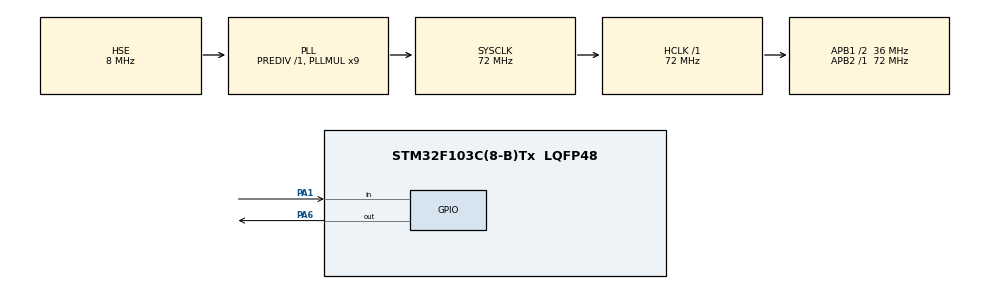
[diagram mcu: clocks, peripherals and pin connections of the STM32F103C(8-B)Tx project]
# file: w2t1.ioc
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Mcu.Family=STM32F1
Mcu.Name=STM32F103C(8-B)Tx
Mcu.Package=LQFP48
NVIC.PriorityGroup=NVIC_PRIORITYGROUP_4
NVIC.TIM2_IRQn=true\:0\:0\:false\:false\:true\:true\:true\:true
PA1.GPIO_PuPd=GPIO_PULLUP
PA1.Signal=GPIO_Input
PA13.Mode=Serial_Wire
PA13.Signal=SYS_JTMS-SWDIO
PA14.Mode=Serial_Wire
PA14.Signal=SYS_JTCK-SWCLK
PA6.PinState=GPIO_PIN_SET
PA6.Signal=GPIO_Output
PD0-OSC_IN.Mode=HSE-External-Oscillator
PD0-OSC_IN.Signal=RCC_OSC_IN
PD1-OSC_OUT.Mode=HSE-External-Oscillator
PD1-OSC_OUT.Signal=RCC_OSC_OUT
ProjectManager.HeapSize=0x200
ProjectManager.StackSize=0x400
ProjectManager.TargetToolchain=MDK-ARM V5.32
RCC.AHBFreq_Value=72000000
RCC.APB1CLKDivider=RCC_HCLK_DIV2
RCC.APB1Freq_Value=36000000
RCC.APB1TimFreq_Value=72000000
RCC.APB2Freq_Value=72000000
RCC.APB2TimFreq_Value=72000000
RCC.HCLKFreq_Value=72000000
RCC.PLLMUL=RCC_PLL_MUL9
RCC.PLLSourceVirtual=RCC_PLLSOURCE_HSE
RCC.SYSCLKFreq_VALUE=72000000
RCC.SYSCLKSource=RCC_SYSCLKSOURCE_PLLCLK
RCC.USBFreq_Value=72000000
TIM2.Period=9999
TIM2.Prescaler=71
VP_TIM2_VS_ClockSourceINT.Mode=Internal
board=custom

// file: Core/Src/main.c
/* USER CODE BEGIN Header */
/**
  ******************************************************************************
  * @file           : main.c
  * @brief          : Main program body
  ******************************************************************************
  * @attention
  *
  * Copyright (c) 2026 STMicroelectronics.
  * All rights reserved.
  *
  * This software is licensed under terms that can be found in the LICENSE file
  * in the root directory of this software component.
  * If no LICENSE file comes with this software, it is provided AS-IS.
  *
  ******************************************************************************
  */
/* USER CODE END Header */
#include "main.h"
#include "stm32f103xb.h"
#include "stm32f1xx_hal_gpio.h"
#include "stm32f1xx_hal_tim.h"
#include <stdint.h>

TIM_HandleTypeDef htim2;

/* USER CODE BEGIN PV */
uint8_t key_state = 0;
uint16_t press_cnt = 0;
uint8_t is_5hz = 0;
uint8_t led_mode = 0; // 0 是灭 1 是亮
uint8_t nowledpin = 0;
uint16_t blink_cnt = 0;

/* USER CODE END PV */

void SystemClock_Config(void);
static void MX_GPIO_Init(void);
static void MX_TIM2_Init(void);

int main(void)
{

  /* MCU Configuration--------------------------------------------------------*/

  /* Reset of all peripherals, Initializes the Flash interface and the Systick. */
  HAL_Init();

  /* Configure the system clock */
  SystemClock_Config();

  /* Initialize all configured peripherals */
  MX_GPIO_Init();
  MX_TIM2_Init();
  /* USER CODE BEGIN 2 */
HAL_TIM_Base_Start_IT(&htim2);
  /* USER CODE END 2 */

  /* Infinite loop */
  while (1)
  {

  }
}

void SystemClock_Config(void)
{
  RCC_OscInitTypeDef RCC_OscInitStruct = {0};
  RCC_ClkInitTypeDef RCC_ClkInitStruct = {0};

  /** Initializes the RCC Oscillators according to the specified parameters
  * in the RCC_OscInitTypeDef structure.
  */
  RCC_OscInitStruct.OscillatorType = RCC_OSCILLATORTYPE_HSE;
  RCC_OscInitStruct.HSEState = RCC_HSE_ON;
  RCC_OscInitStruct.HSEPredivValue = RCC_HSE_PREDIV_DIV1;
  RCC_OscInitStruct.HSIState = RCC_HSI_ON;
  RCC_OscInitStruct.PLL.PLLState = RCC_PLL_ON;
  RCC_OscInitStruct.PLL.PLLSource = RCC_PLLSOURCE_HSE;
  RCC_OscInitStruct.PLL.PLLMUL = RCC_PLL_MUL9;
  if (HAL_RCC_OscConfig(&RCC_OscInitStruct) != HAL_OK)
  {
    Error_Handler();
  }

  /** Initializes the CPU, AHB and APB buses clocks
  */
  RCC_ClkInitStruct.ClockType = RCC_CLOCKTYPE_HCLK|RCC_CLOCKTYPE_SYSCLK
                              |RCC_CLOCKTYPE_PCLK1|RCC_CLOCKTYPE_PCLK2;
  RCC_ClkInitStruct.SYSCLKSource = RCC_SYSCLKSOURCE_PLLCLK;
  RCC_ClkInitStruct.AHBCLKDivider = RCC_SYSCLK_DIV1;
  RCC_ClkInitStruct.APB1CLKDivider = RCC_HCLK_DIV2;
  RCC_ClkInitStruct.APB2CLKDivider = RCC_HCLK_DIV1;

  if (HAL_RCC_ClockConfig(&RCC_ClkInitStruct, FLASH_LATENCY_2) != HAL_OK)
  {
    Error_Handler();
  }
}

static void MX_TIM2_Init(void)
{

  TIM_ClockConfigTypeDef sClockSourceConfig = {0};
  TIM_MasterConfigTypeDef sMasterConfig = {0};

  htim2.Instance = TIM2;
  htim2.Init.Prescaler = 71;
  htim2.Init.CounterMode = TIM_COUNTERMODE_UP;
  htim2.Init.Period = 9999;
  htim2.Init.ClockDivision = TIM_CLOCKDIVISION_DIV1;
  htim2.Init.AutoReloadPreload = TIM_AUTORELOAD_PRELOAD_DISABLE;
  if (HAL_TIM_Base_Init(&htim2) != HAL_OK)
  {
    Error_Handler();
  }
  sClockSourceConfig.ClockSource = TIM_CLOCKSOURCE_INTERNAL;
  if (HAL_TIM_ConfigClockSource(&htim2, &sClockSourceConfig) != HAL_OK)
  {
    Error_Handler();
  }
  sMasterConfig.MasterOutputTrigger = TIM_TRGO_RESET;
  sMasterConfig.MasterSlaveMode = TIM_MASTERSLAVEMODE_DISABLE;
  if (HAL_TIMEx_MasterConfigSynchronization(&htim2, &sMasterConfig) != HAL_OK)
  {
    Error_Handler();
  }

}

static void MX_GPIO_Init(void)
{
  GPIO_InitTypeDef GPIO_InitStruct = {0};

  /* GPIO Ports Clock Enable */
  __HAL_RCC_GPIOD_CLK_ENABLE();
  __HAL_RCC_GPIOA_CLK_ENABLE();

  /*Configure GPIO pin Output Level */
  HAL_GPIO_WritePin(GPIOA, GPIO_PIN_6, GPIO_PIN_SET);

  /*Configure GPIO pin : PA1 */
  GPIO_InitStruct.Pin = GPIO_PIN_1;
  GPIO_InitStruct.Mode = GPIO_MODE_INPUT;
  GPIO_InitStruct.Pull = GPIO_PULLUP;
  HAL_GPIO_Init(GPIOA, &GPIO_InitStruct);

  /*Configure GPIO pin : PA6 */
  GPIO_InitStruct.Pin = GPIO_PIN_6;
  GPIO_InitStruct.Mode = GPIO_MODE_OUTPUT_PP;
  GPIO_InitStruct.Pull = GPIO_NOPULL;
  GPIO_InitStruct.Speed = GPIO_SPEED_FREQ_LOW;
  HAL_GPIO_Init(GPIOA, &GPIO_InitStruct);

}

/* USER CODE BEGIN 4 */
void flashing5hz(void)
{
  if (is_5hz == 1) {
    blink_cnt ++;
    if (blink_cnt >=10) {
      HAL_GPIO_TogglePin(GPIOA, GPIO_PIN_6);
      blink_cnt = 0;
    }
  }
}

void short_switch(void)
{
  is_5hz = 0;
  HAL_GPIO_TogglePin(GPIOA, GPIO_PIN_6);
}

void long_switch(void)
{
  blink_cnt = 0;
  if (is_5hz == 0 ) {
  nowledpin = HAL_GPIO_ReadPin(GPIOA, GPIO_PIN_6);
  is_5hz = 1;
  }else {
  is_5hz = 0;
  HAL_GPIO_WritePin(GPIOA, GPIO_PIN_6, nowledpin);
  }
}

void HAL_TIM_PeriodElapsedCallback(TIM_HandleTypeDef *htim)
{
  if (htim ->Instance == TIM2) {
    uint8_t now_state = HAL_GPIO_ReadPin(GPIOA, GPIO_PIN_1);//补充:按下是低电平 最好还是宏定义
    switch (key_state) {
    case 0:
    {
      if (now_state == 0) { //按钮按下了
        key_state = 1;
        press_cnt ++;
      }
      break;
    }

    case 1:
    {
      if (now_state == 1) { //松手或者发生抖动了!
        if (press_cnt < 2) {
        ;  //棍母//欸不是这里怎么打了注释符号没有注释啊
        /////////////////////////////////进入20ms误触的消抖
        }

        else if (press_cnt <100) {
        short_switch();
        /////////////进入短按切换函数
        }

        else if (press_cnt >= 100) {
        long_switch();
        /////////////进入长按切换函数
        }

        press_cnt = 0;
        key_state = 0;
      }
      //一直按着
      else {
      press_cnt ++;
      }
    }
    }
    flashing5hz();
  }
}

/* USER CODE END 4 */

void Error_Handler(void)
{
  __disable_irq();
  while (1)
  {
  }
}
